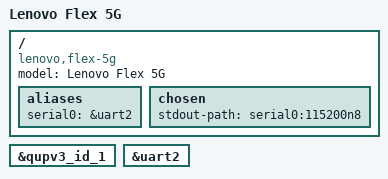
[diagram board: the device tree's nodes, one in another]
// SPDX-License-Identifier: BSD-3-Clause
/*
 * Copyright (c) 2017-2019, The Linux Foundation. All rights reserved.
 * Copyright (c) 2020, Linaro Limited
 */

/dts-v1/;

#include <dt-bindings/regulator/qcom,rpmh-regulator.h>
#include <dt-bindings/gpio/gpio.h>
#include "sc8180x.dtsi"
//#include "pm8150.dtsi"
//#include "pm8150b.dtsi"
//#include "pm8150l.dtsi"

/ {
	model = "Lenovo Flex 5G";
	compatible = "lenovo,flex-5g", "qcom,sc8180x";

	aliases {
		serial0 = &uart2;
	};

	chosen {
		stdout-path = "serial0:115200n8";
	};
};

&qupv3_id_1 {
	status = "okay";
};

&uart2 {
	status = "okay";
};
